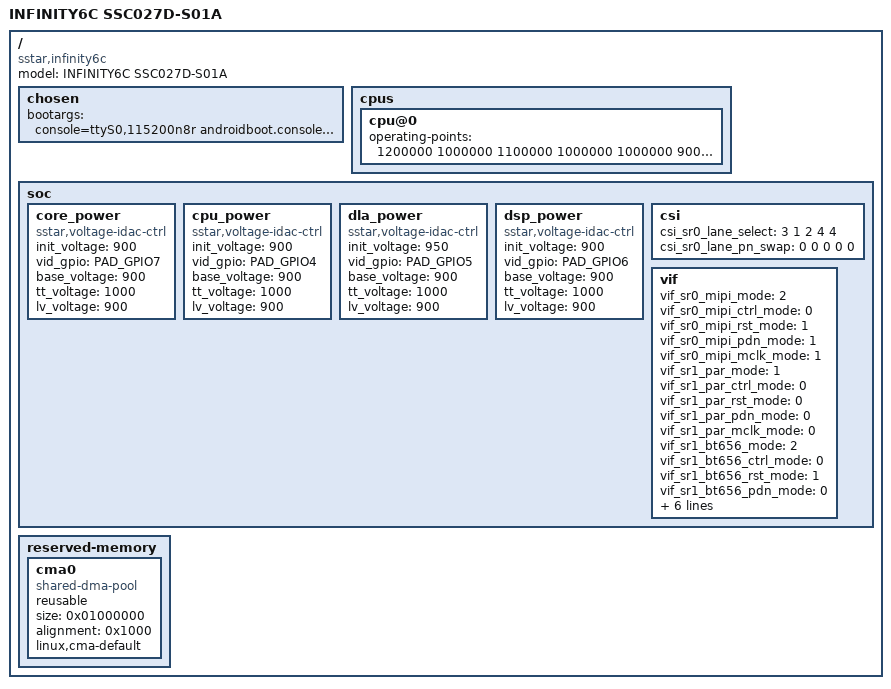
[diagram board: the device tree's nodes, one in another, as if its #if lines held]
/*
* infinity6c-ssc027d-s01a.dts - Sigmastar
*
* Copyright (c) [2019~2020] SigmaStar Technology.
*
*
* This software is licensed under the terms of the GNU General Public
* License version 2, as published by the Free Software Foundation, and
* may be copied, distributed, and modified under those terms.
*
* This program is distributed in the hope that it will be useful,
* but WITHOUT ANY WARRANTY; without even the implied warranty of
* MERCHANTABILITY or FITNESS FOR A PARTICULAR PURPOSE.  See the
* GNU General Public License version 2 for more details.
*
*/

 /*
 * Memory Layout
 * 0x20000000-0x24000000 64M Kernel
 * 0x24000000-0x24800000 8M  system
 * 0x24800000-0x24900000 1M  data
 * 0x24900000-0x25000000 7M  temp0
 * 0x25000000-0x28000000 48M temp1
 */
/dts-v1/;
#include "infinity6c.dtsi"
#include "infinity6c-ssc027d-s01a-padmux.dtsi"

/ {
    #address-cells = <1>;
    #size-cells = <1>;
    model = "INFINITY6C SSC027D-S01A";
    compatible = "sstar,infinity6c";

    chosen {
        bootargs = "console=ttyS0,115200n8r androidboot.console=ttyS0 user_debug=31 root=/dev/mtdblock0 init=/linuxrc LX_MEM=0x04000000 mma_heap=mma_heap_name0,miu=0,sz=0x2000000,max_start_off=0x22000000 mma_memblock_remove=1 cma=2M nohz=off";
    };

    cpus {
          cpu@0 {
                operating-points = <
                    /* kHz     uV */
                    1200000  1000000
                    1100000  1000000
                    1000000  900000
                    900000   900000
                    800000   850000
                    600000   850000
                >;
          };
    };
    soc {
#if CONFIG_SS_VOLTAGE_IDAC_CTRL
        core_power {
            compatible = "sstar,voltage-idac-ctrl";
            init_voltage = <900>;
            vid_gpio = <PAD_GPIO7>;
            base_voltage = <900>;
            tt_voltage = <1000>;
            lv_voltage = <900>;
            status = "ok";
        };
        cpu_power {
            compatible = "sstar,voltage-idac-ctrl";
            init_voltage = <900>;
            vid_gpio = <PAD_GPIO4>;
            base_voltage = <900>;
            tt_voltage = <1000>;
            lv_voltage = <900>;
            status = "ok";
        };
        dla_power {
            compatible = "sstar,voltage-idac-ctrl";
            init_voltage = <950>;
            vid_gpio = <PAD_GPIO5>;
            base_voltage = <900>;
            tt_voltage = <1000>;
            lv_voltage = <900>;
            status = "ok";
        };
        dsp_power {
            compatible = "sstar,voltage-idac-ctrl";
            init_voltage = <900>;
            vid_gpio = <PAD_GPIO6>;
            base_voltage = <900>;
            tt_voltage = <1000>;
            lv_voltage = <900>;
            status = "ok";
        };
#endif
        csi: csi {
            /* Config lane selection */
            csi_sr0_lane_select = <3 1 2 4 4>;
            /* Config lane P/N swap */
            csi_sr0_lane_pn_swap = <0 0 0 0 0>;
        };
        vif: vif {
            /* Config sensor 0 pad mux */
            vif_sr0_mipi_mode         = <2>;
            vif_sr0_mipi_ctrl_mode    = <0>;
            vif_sr0_mipi_rst_mode     = <1>;
            vif_sr0_mipi_pdn_mode     = <1>;
            vif_sr0_mipi_mclk_mode    = <1>;

            /* Config sensor 1 pad mux */
            vif_sr1_par_mode          = <1>;
            vif_sr1_par_ctrl_mode     = <0>;
            vif_sr1_par_rst_mode      = <0>;
            vif_sr1_par_pdn_mode      = <0>;
            vif_sr1_par_mclk_mode     = <0>;
            vif_sr1_bt656_mode        = <2>;
            vif_sr1_bt656_ctrl_mode   = <0>;
            vif_sr1_bt656_rst_mode    = <1>;
            vif_sr1_bt656_pdn_mode    = <0>;
            vif_sr1_bt656_mclk_mode   = <0>;

            /* Config sensor 2 pad mux */
            vif_sr2_mipi_mode         = <0>;
            vif_sr2_mipi_ctrl_mode    = <0>;
            vif_sr2_mipi_rst_mode     = <0>;
            vif_sr2_mipi_pdn_mode     = <0>;
            vif_sr2_mipi_mclk_mode    = <0>;
        };
    };

/*!!IMPORTANT!! The reserved memory must be 1MB aligned*/
    reserved-memory {
        #address-cells = <1>;
        #size-cells = <1>;
        ranges;

        cma0 {
            compatible = "shared-dma-pool";
            reusable;
            size = <0x01000000>;
            alignment = <0x1000>;
            linux,cma-default;
        };
    };
};
